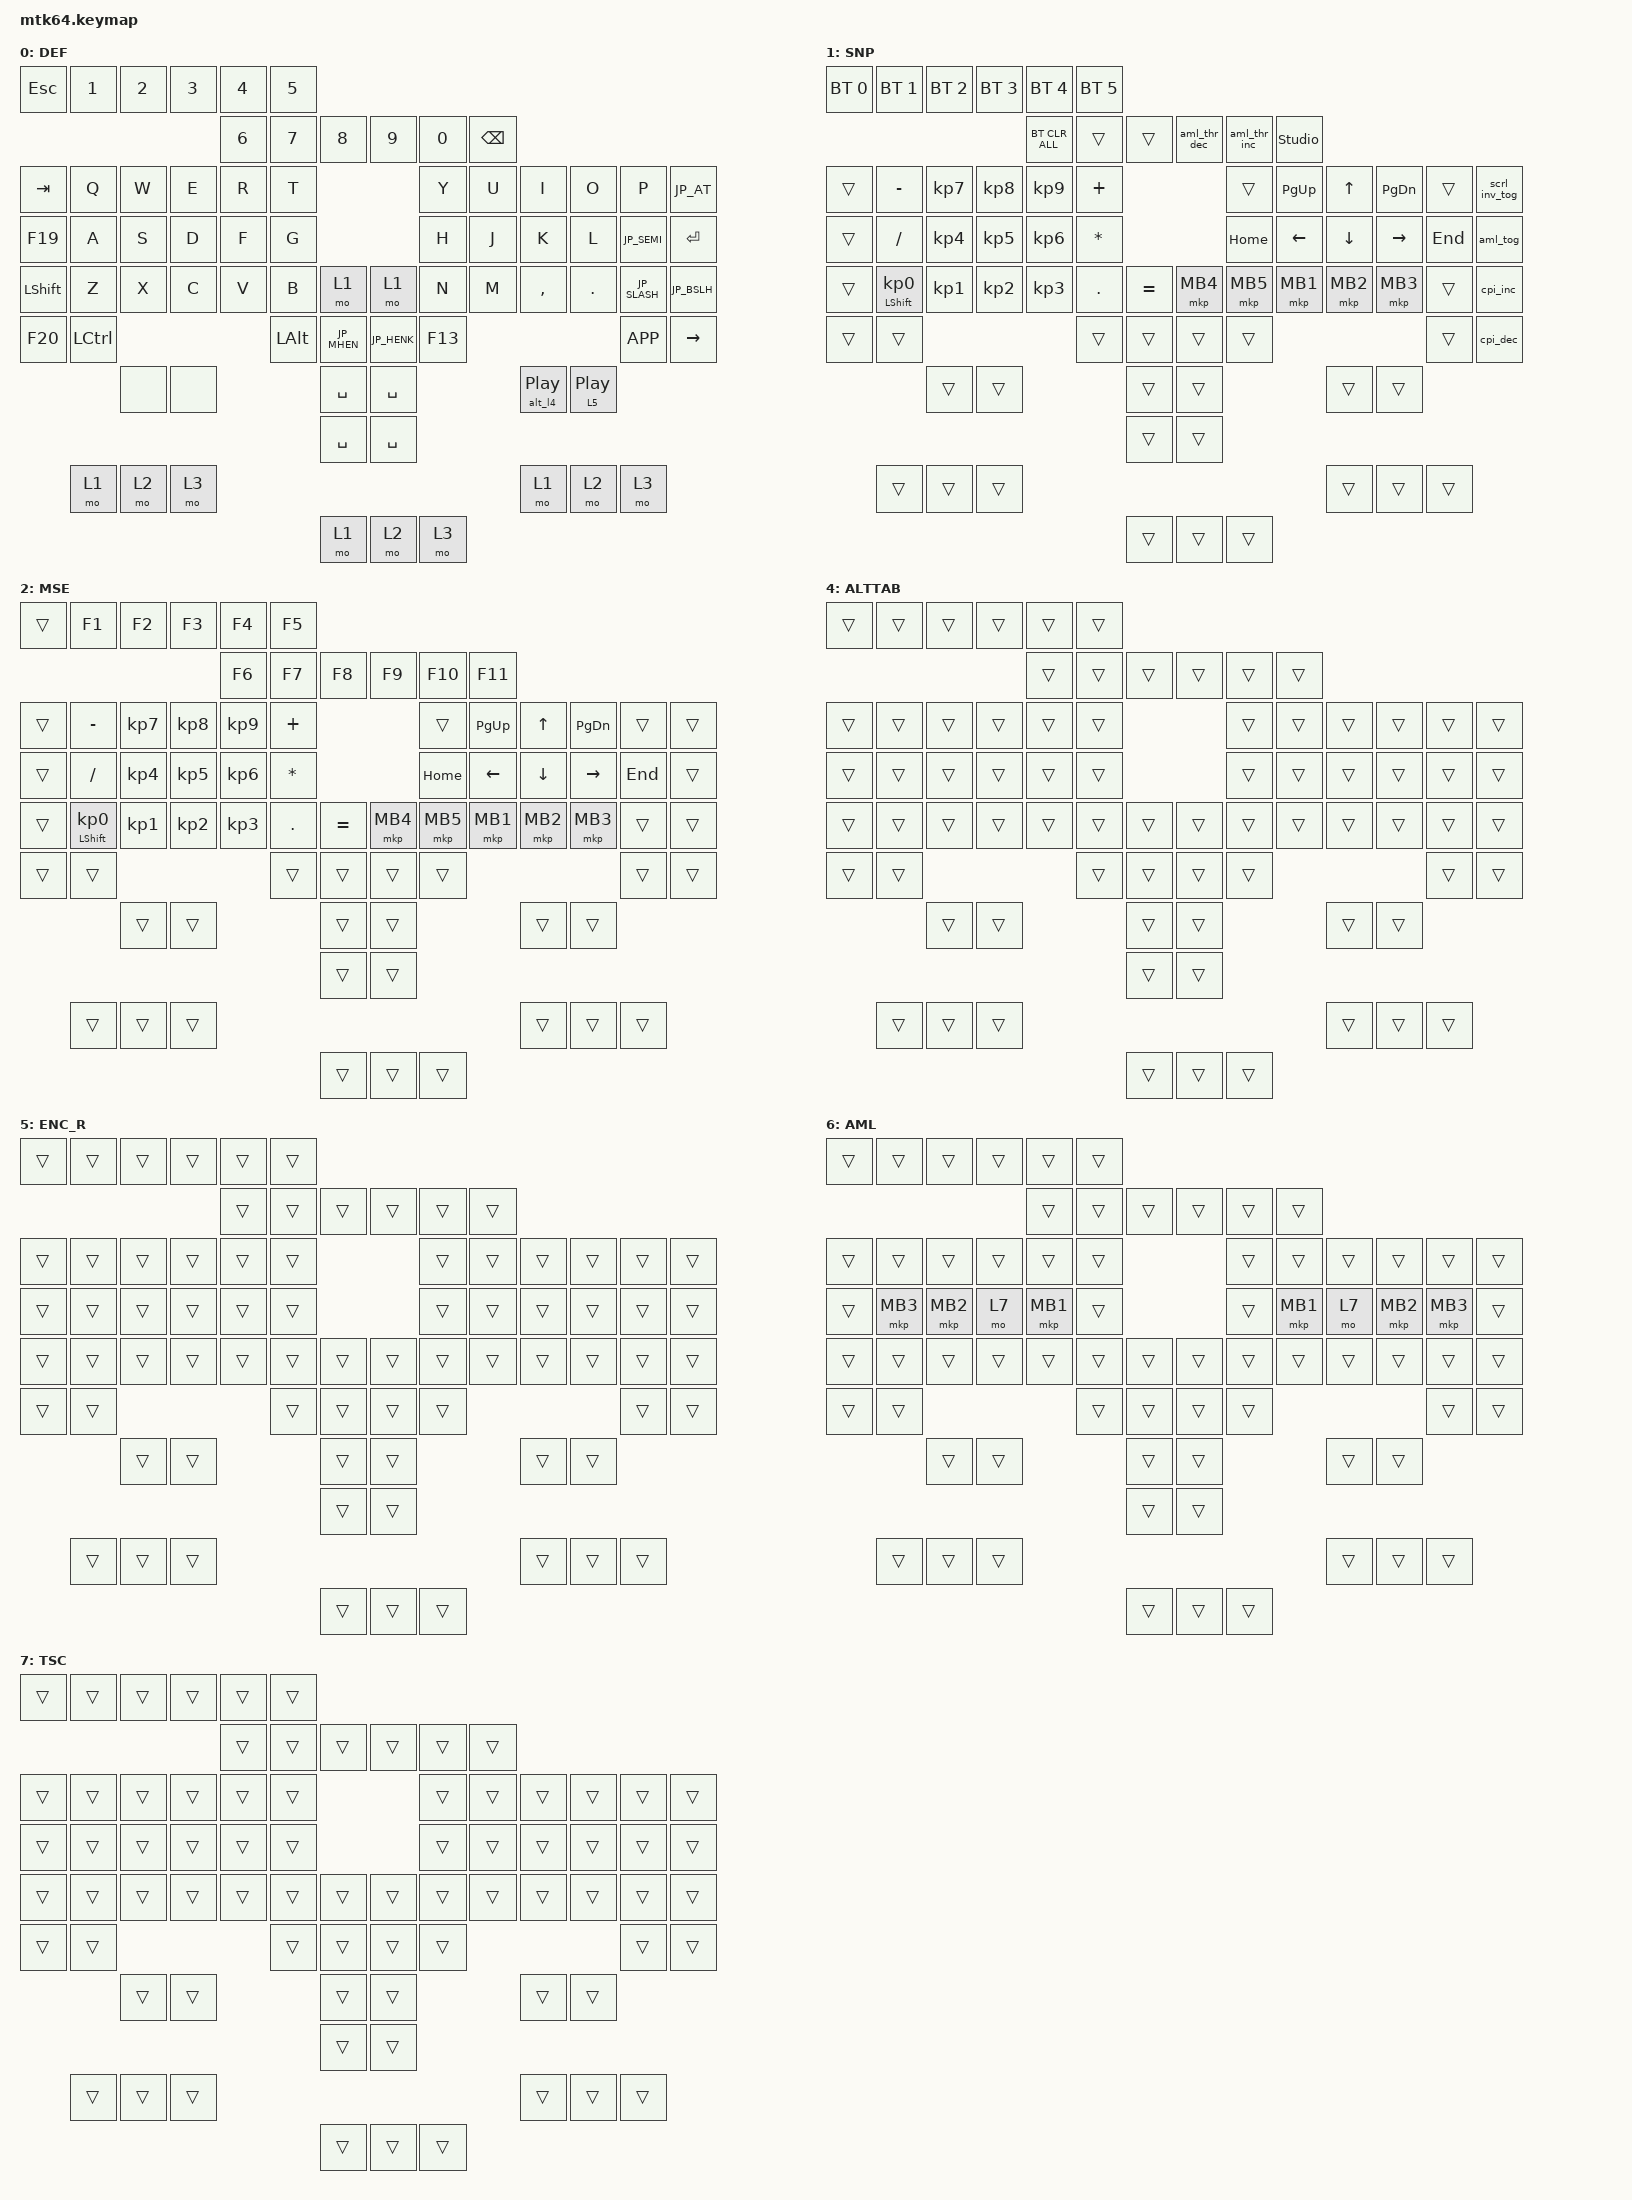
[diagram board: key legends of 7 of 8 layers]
#include <behaviors.dtsi>
#include <dt-bindings/zmk/bt.h>
#include <dt-bindings/zmk/keys.h>
#include <dt-bindings/zmk/pointing.h>
#include <input/processors.dtsi>
#include "keycode_japanese.h"

// スクロール量の設定
#define ZMK_POINTING_DEFAULT_SCRL_VAL 100

&mt {
    flavor = "balanced";
    quick-tap-ms = <0>;
};

&mkp_input_listener {
    input-processors = <&zip_aml 6 500>;
};

/ {
    behaviors {
        // 垂直スクロール用のbehaviorの設定
        scroll_up_down: behavior_sensor_rotate_mouse_wheel_up_down {
            compatible = "zmk,behavior-sensor-rotate-var";
            #sensor-binding-cells = <2>;
            bindings = <&msc>, <&msc>;
            tap-ms = <20>; // スクロールのタップ時間
        };
        // エンコーダー押し込み: 単押し=再生/停止、押し込んだまま回す=L4
        enc_push: enc_push {
            compatible = "zmk,behavior-hold-tap";
            #binding-cells = <2>;
            flavor = "tap-preferred";
            tapping-term-ms = <150>;
            bindings = <&mo>, <&kp>;
        };
        // 左エンコーダー押し込み: 単押し=再生/停止、押し込んだまま=Alt押しっぱなし+L4 (回してウィンドウ選択、離して決定)
        alt_l4: alt_l4 {
            compatible = "zmk,behavior-macro";
            #binding-cells = <0>;
            wait-ms = <0>;
            tap-ms = <0>;
            bindings
                = <&macro_press &kp LALT &mo 4>
                , <&macro_pause_for_release>
                , <&macro_release &mo 4 &kp LALT>
                ;
        };

        enc_push_alt: enc_push_alt {
            compatible = "zmk,behavior-hold-tap";
            #binding-cells = <2>;
            flavor = "tap-preferred";
            tapping-term-ms = <150>;
            bindings = <&alt_l4>, <&kp>;
        };

        // 水平スクロール用のbehaviorの設定
        scroll_left_right: behavior_sensor_rotate_mouse_wheel_left_right {
            compatible = "zmk,behavior-sensor-rotate-var";
            #sensor-binding-cells = <2>;
            bindings = <&msc>, <&msc>;
            tap-ms = <20>; // スクロールのタップ時間
        };
    };
};

/ {


    // 応急処置: 基板の不具合で Enter / BS と同時に @ が誤入力されるのを打ち消す
    combos {
        compatible = "zmk,combos";
        ghost_at_enter {
            timeout-ms = <30>;
            key-positions = <23 35>;
            bindings = <&kp ENTER>;
            layers = <0>;
        };
        ghost_at_bspc {
            timeout-ms = <30>;
            key-positions = <23 11>;
            bindings = <&kp BSPC>;
            layers = <0>;
        };
    };

    keymap {
        compatible = "zmk,keymap";

        default_layer {
            display-name = "DEF";
            bindings = <
// Keyball61 (Remap) の Layer 0 を移植
&kp ESC    &kp N1    &kp N2  &kp N3  &kp N4  &kp N5                                      &kp N6  &kp N7  &kp N8     &kp N9   &kp N0       &kp BSPC
&kp TAB    &kp Q     &kp W   &kp E   &kp R   &kp T                                       &kp Y   &kp U   &kp I      &kp O    &kp P        &kp JP_AT
&kp F19    &kp A     &kp S   &kp D   &kp F   &kp G                                       &kp H   &kp J   &kp K      &kp L    &kp JP_SEMI  &kp ENTER
&kp LSHFT  &kp Z     &kp X   &kp C   &kp V   &kp B   &mo 1                 &mo 1   &kp N   &kp M   &kp COMMA  &kp DOT  &kp JP_SLASH &kp JP_BSLH
&kp F20    &kp LCTRL                 &kp LALT  &kp JP_MHEN          &kp JP_HENK      &kp F13                                   &kp K_APP     &kp RIGHT
                 &none &none                &kp SPACE          &kp SPACE                   &enc_push_alt 0 C_PP &enc_push 5 C_PP
                                                 &kp SPACE          &kp SPACE
          &mo 1  &mo 2  &mo 3                                                                   &mo 1     &mo 2   &mo 3
                                                 &mo 1    &mo 2     &mo 3  
            >;

            sensor-bindings = <
                &inc_dec_kp LEFT RIGHT            // 右エンコーダー(sensor0): ←/→
                &inc_dec_kp C_VOL_DN C_VOL_UP   // 左エンコーダー(sensor1): 音量
            >;
        };

        layer_1 {
            display-name = "SNP";
            bindings = <
&bt BT_SEL 0  &bt BT_SEL 1  &bt BT_SEL 2  &bt BT_SEL 3  &bt BT_SEL 4  &bt BT_SEL 5
                                                                    &bt BT_CLR_ALL  &trans  &trans  &aml_thr_dec  &aml_thr_inc  &studio_unlock
&trans  &kp MINUS                   &kp KP_NUMBER_7  &kp KP_NUMBER_8  &kp KP_NUMBER_9  &kp PLUS                                    &trans            &kp PG_UP          &kp UP_ARROW    &kp PG_DN             &trans                &scrl_inv_tog  
&trans  &kp SLASH                   &kp KP_NUMBER_4  &kp KP_NUMBER_5  &kp KP_NUMBER_6  &kp ASTERISK                                &kp HOME          &kp LEFT_ARROW     &kp DOWN_ARROW  &kp RIGHT_ARROW       &kp END               &aml_tog  
&trans  &mt LEFT_SHIFT KP_NUMBER_0  &kp KP_NUMBER_1  &kp KP_NUMBER_2  &kp KP_NUMBER_3  &kp PERIOD    &kp EQUAL      &mkp MB4       &mkp MB5          &mkp MB1           &mkp MB2        &mkp MB3              &trans                &cpi_inc
&trans  &trans                                                                         &trans        &trans         &trans         &trans                                                                     &trans                &cpi_dec
                                    &trans           &trans                                          &trans         &trans                                              &trans          &trans
                                                                                                     &trans         &trans
        &trans                      &trans           &trans                                                                                                             &trans          &trans                &trans
                                                                                                     &trans &trans  &trans 
            >;
        };

        layer_2 {
            display-name = "MSE";
            bindings = <
&trans  &kp F1                      &kp F2           &kp F3           &kp F4           &kp F5                                      &kp F6            &kp F7             &kp F8          &kp F9                &kp F10               &kp F11
&trans  &kp MINUS                   &kp KP_NUMBER_7  &kp KP_NUMBER_8  &kp KP_NUMBER_9  &kp PLUS                                    &trans            &kp PG_UP          &kp UP_ARROW    &kp PG_DN             &trans                &trans  
&trans  &kp SLASH                   &kp KP_NUMBER_4  &kp KP_NUMBER_5  &kp KP_NUMBER_6  &kp ASTERISK                                &kp HOME          &kp LEFT_ARROW     &kp DOWN_ARROW  &kp RIGHT_ARROW       &kp END               &trans  
&trans  &mt LEFT_SHIFT KP_NUMBER_0  &kp KP_NUMBER_1  &kp KP_NUMBER_2  &kp KP_NUMBER_3  &kp PERIOD    &kp EQUAL      &mkp MB4       &mkp MB5          &mkp MB1           &mkp MB2        &mkp MB3              &trans                &trans  
&trans  &trans                                                                         &trans        &trans         &trans         &trans                                                                     &trans                &trans
                                    &trans           &trans                                          &trans         &trans                                              &trans          &trans
                                                                                                     &trans         &trans
        &trans                      &trans           &trans                                                                                                             &trans          &trans                &trans
                                                                                                     &trans &trans  &trans 
            >;
            sensor-bindings = <
                &inc_dec_kp TAB LS(TAB) 
                &inc_dec_kp PG_UP PG_DN
            >;
        };

        layer_3 {
            display-name = "SCR";
            bindings = <
&kp ESCAPE      &kp LC(LS(TAB))         &kp UP_ARROW    &kp LC(TAB)              &trans   &trans                                    &trans  &trans  &trans  &trans  &trans  &trans
&kp HOME        &kp LEFT_ARROW          &kp DOWN_ARROW  &kp RIGHT_ARROW          &kp END  &trans                                    &trans  &trans  &trans  &trans  &trans  &trans
&kp LEFT_SHIFT  &kp LG(LS(LEFT_ARROW))  &trans          &kp LG(LS(RIGHT_ARROW))  &trans   &trans     &trans         &trans          &trans  &trans  &trans  &trans  &trans  &trans
&trans          &trans                                                                               &trans         &trans                          &trans  &trans
                                        &trans          &trans                                       &trans         &trans          &trans  &trans
                                                                                                     &trans         &trans
                &trans                  &trans          &trans                                                                      &trans  &trans  &trans
            >;
            sensor-bindings = <
                &scroll_left_right SCRL_LEFT SCRL_RIGHT
                &scroll_up_down SCRL_UP SCRL_DOWN
            >;
        };

        layer_4 {
            display-name = "ALTTAB";
            bindings = <
&trans  &trans  &trans  &trans  &trans  &trans                      &trans  &trans  &trans  &trans  &trans  &trans
&trans  &trans  &trans  &trans  &trans  &trans                      &trans  &trans  &trans  &trans  &trans  &trans
&trans  &trans  &trans  &trans  &trans  &trans                      &trans  &trans  &trans  &trans  &trans  &trans
&trans  &trans  &trans  &trans  &trans  &trans  &trans      &trans  &trans  &trans  &trans  &trans  &trans  &trans
&trans  &trans                          &trans  &trans      &trans  &trans                          &trans  &trans
                &trans  &trans                  &trans      &trans                  &trans  &trans
                                                &trans      &trans
        &trans  &trans  &trans                                                      &trans  &trans  &trans
                                               &trans &trans &trans
            >;
            sensor-bindings = <
                &inc_dec_kp UP DOWN              // (右) 左押し込み中は使わない
                &inc_dec_kp LS(TAB) TAB          // 左エンコーダー押し込み中: Alt+Tab でウィンドウ選択
            >;
        };

        layer_5 {
            display-name = "ENC_R";
            bindings = <
&trans  &trans  &trans  &trans  &trans  &trans                      &trans  &trans  &trans  &trans  &trans  &trans
&trans  &trans  &trans  &trans  &trans  &trans                      &trans  &trans  &trans  &trans  &trans  &trans
&trans  &trans  &trans  &trans  &trans  &trans                      &trans  &trans  &trans  &trans  &trans  &trans
&trans  &trans  &trans  &trans  &trans  &trans  &trans      &trans  &trans  &trans  &trans  &trans  &trans  &trans
&trans  &trans                          &trans  &trans      &trans  &trans                          &trans  &trans
                &trans  &trans                  &trans      &trans                  &trans  &trans
                                                &trans      &trans
        &trans  &trans  &trans                                                      &trans  &trans  &trans
                                               &trans &trans &trans
            >;
            sensor-bindings = <
                &inc_dec_kp UP DOWN              // 右エンコーダー押し込み中: ↑/↓
                &inc_dec_kp C_VOL_DN C_VOL_UP    // (左) 音量のまま
            >;
        };

        layer_6 {
            display-name = "AML";
            bindings = <
// takashicompany 方式: 左 S/D/F = 右クリック/スクロール/左クリック, 右 J/K/L = 左クリック/スクロール/中クリック
&trans  &trans  &trans    &trans  &trans    &trans                      &trans  &trans    &trans  &trans    &trans  &trans
&trans  &trans  &trans    &trans  &trans    &trans                      &trans  &trans    &trans  &trans    &trans  &trans
&trans  &mkp MB3  &mkp MB2  &mo 7   &mkp MB1  &trans                      &trans  &mkp MB1  &mo 7   &mkp MB2  &mkp MB3  &trans
&trans  &trans  &trans    &trans  &trans    &trans  &trans      &trans  &trans  &trans    &trans  &trans    &trans  &trans
&trans  &trans                          &trans  &trans      &trans  &trans                          &trans  &trans
                &trans  &trans                  &trans      &trans                  &trans  &trans
                                                &trans      &trans
        &trans  &trans  &trans                                                      &trans  &trans  &trans
                                               &trans &trans &trans 
            >;
        };

        layer_7 {
            display-name = "TSC";
            // 自動マウスレイヤーのスクロールキー押下中のみ有効 (ボール -> スクロール)
            bindings = <
&trans  &trans  &trans  &trans  &trans  &trans                      &trans  &trans  &trans  &trans  &trans  &trans
&trans  &trans  &trans  &trans  &trans  &trans                      &trans  &trans  &trans  &trans  &trans  &trans
&trans  &trans  &trans  &trans  &trans  &trans                      &trans  &trans  &trans  &trans  &trans  &trans
&trans  &trans  &trans  &trans  &trans  &trans  &trans      &trans  &trans  &trans  &trans  &trans  &trans  &trans
&trans  &trans                          &trans  &trans      &trans  &trans                          &trans  &trans
                &trans  &trans                  &trans      &trans                  &trans  &trans
                                                &trans      &trans
        &trans  &trans  &trans                                                      &trans  &trans  &trans
                                               &trans &trans &trans
            >;
        };
    };
};
